# ATxmega256A3B device description
Architecture: AVR8_XMEGA; Family: AVR XMEGA
Registers are 8-bit, access not given, no defined reset value unless marked. A register's access mark holds for its fields unless they carry their own. Offsets are from the block's base; [hi:lo] are bit positions; {n}, {i} and the like mark numbered series; 'fields as' and 'values as' point back to an identical list.

## NVM_FUSES — Fuses
Instances: FUSE 0x00 in fuses
0x00 FUSEBYTE0 reset 0xFF — JTAG User ID
  [7:0] JTAGUSERID
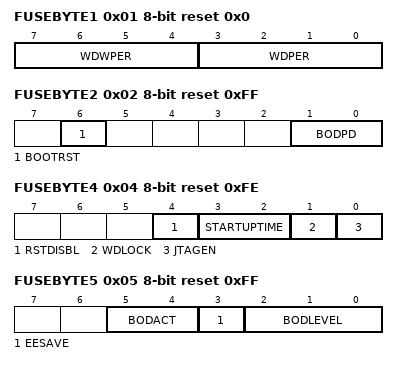
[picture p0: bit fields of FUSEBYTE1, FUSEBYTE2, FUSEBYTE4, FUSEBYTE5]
0x01 FUSEBYTE1 reset 0x0 — Watchdog Configuration
  [7:4] WDWPER — Watchdog Window Timeout Period
    0=8CLK (8 cycles (8ms @ 3.3V)); 1=16CLK (16 cycles (16ms @ 3.3V)); 2=32CLK (32 cycles (32ms @ 3.3V)); 3=64CLK (64 cycles (64ms @ 3.3V)); 4=128CLK (128 cycles (0.125s @ 3.3V)); 5=256CLK (256 cycles (0.25s @ 3.3V)); 6=512CLK (512 cycles (0.5s @ 3.3V)); 7=1KCLK (1K cycles (1s @ 3.3V)); 8=2KCLK (2K cycles (2s @ 3.3V)); 9=4KCLK (4K cycles (4s @ 3.3V)); 10=8KCLK (8K cycles (8s @ 3.3V))
  [3:0] WDPER — Watchdog Timeout Period
    values as WDWPER
0x02 FUSEBYTE2 reset 0xFF — Reset Configuration
  [6] BOOTRST — Boot Loader Section Reset Vector
    0=BOOTLDR (Boot Loader Reset); 1=APPLICATION (Application Reset)
  [1:0] BODPD — BOD Operation in Power-Down Mode
    1=INSAMPLEDMODE (BOD enabled in sampled mode); 2=CONTINOUSLY (BOD enabled continuously); 3=DISABLED (BOD Disabled)
0x04 FUSEBYTE4 reset 0xFE — Start-up Configuration
  [4] RSTDISBL — External Reset Disable
  [3:2] STARTUPTIME
    3=0MS; 1=4MS; 0=64MS
  [1] WDLOCK — Watchdog Timer Lock
  [0] JTAGEN — JTAG Interface Enable
0x05 FUSEBYTE5 reset 0xFF — EESAVE and BOD Level
  [5:4] BODACT — BOD Operation in Active Mode
    values as FUSEBYTE2.BODPD
  [3] EESAVE — Preserve EEPROM Through Chip Erase
  [2:0] BODLEVEL — Brownout Detection Voltage Level
    7=1V6 (1.6 V); 6=1V9 (1.9 V); 5=2V1 (2.1 V); 4=2V4 (2.4 V); 3=2V6 (2.6 V); 2=2V9 (2.9 V); 1=3V2 (3.2 V); 0=3V4 (3.4 V)

## NVM_PROD_SIGNATURES — Production Signatures
Instances: PROD_SIGNATURES 0x00 in prod_signatures
0x00 RCOSC2M — RCOSC 2MHz Calibration Value
0x02 RCOSC32K — RCOSC 32kHz Calibration Value
0x03 RCOSC32M — RCOSC 32MHz Calibration Value
{0x8+i} LOTNUM{i} (i=0..5) — Lot Number Byte {i}, ASCII
0x10 WAFNUM — Wafer Number
0x12 COORDX0 — Wafer Coordinate X Byte 0
0x13 COORDX1 — Wafer Coordinate X Byte 1
0x14 COORDY0 — Wafer Coordinate Y Byte 0
0x15 COORDY1 — Wafer Coordinate Y Byte 1
0x20 ADCACAL0 — ADCA Calibration Byte 0
0x21 ADCACAL1 — ADCA Calibration Byte 1
0x24 ADCBCAL0 — ADCB Calibration Byte 0
0x25 ADCBCAL1 — ADCB Calibration Byte 1
0x2E TEMPSENSE0 — Temperature Sensor Calibration Byte 0
0x2F TEMPSENSE1 — Temperature Sensor Calibration Byte 0
0x30 DACAOFFCAL — DACA Calibration Byte 0
0x31 DACAGAINCAL — DACA Calibration Byte 1
0x32 DACBOFFCAL — DACB Calibration Byte 0
0x33 DACBGAINCAL — DACB Calibration Byte 1

## AC — Analog Comparator
Instances: ACA 0x0380, ACB 0x0390
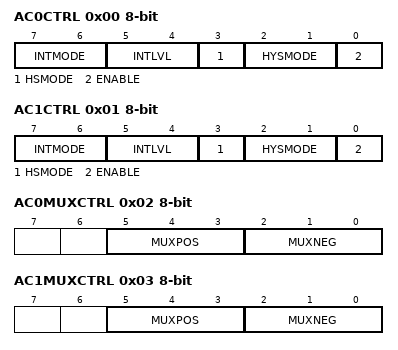
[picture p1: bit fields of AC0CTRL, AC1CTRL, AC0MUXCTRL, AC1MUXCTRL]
0x00 AC0CTRL — Analog Comparator 0 Control
  [7:6] INTMODE — Interrupt Mode
    0=BOTHEDGES (Interrupt on both edges); 2=FALLING (Interrupt on falling edge); 3=RISING (Interrupt on rising edge)
  [5:4] INTLVL — Interrupt Level
    0=OFF (Interrupt disabled); 1=LO (Low level); 2=MED (Medium level); 3=HI (High level)
  [3] HSMODE — High-speed Mode
  [2:1] HYSMODE — Hysteresis Mode
    0=NO (No hysteresis); 1=SMALL (Small hysteresis); 2=LARGE (Large hysteresis)
  [0] ENABLE
0x01 AC1CTRL — Analog Comparator 1 Control
  fields as AC0CTRL
0x02 AC0MUXCTRL — Analog Comparator 0 MUX Control
  [5:3] MUXPOS — MUX Positive Input
    {v}=PIN{v} (v=0..6); 7=DAC (DAC output)
  [2:0] MUXNEG — MUX Negative Input
    0=PIN0; 1=PIN1; 2=PIN3; 3=PIN5; 4=PIN7; 5=DAC (DAC output); 6=BANDGAP (Bandgap Reference); 7=SCALER (Internal voltage scaler)
0x03 AC1MUXCTRL — Analog Comparator 1 MUX Control
  fields as AC0MUXCTRL
0x04 CTRLA — Control Register A
  [0] AC0OUT — Analog Comparator 0 Output Enable
0x05 CTRLB — Control Register B
  [5:0] SCALEFAC — VCC Voltage Scaler Factor
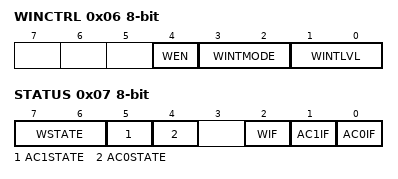
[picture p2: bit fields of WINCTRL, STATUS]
0x06 WINCTRL — Window Mode Control
  [4] WEN — Window Mode Enable
  [3:2] WINTMODE — Window Interrupt Mode
    0=ABOVE (Interrupt on above window); 1=INSIDE (Interrupt on inside window); 2=BELOW (Interrupt on below window); 3=OUTSIDE (Interrupt on outside window)
  [1:0] WINTLVL — Window Interrupt Level
    0=OFF (Interrupt disabled); 1=LO (Low priority); 2=MED (Medium priority); 3=HI (High priority)
0x07 STATUS
  [7:6] WSTATE — Window Mode State
    0=ABOVE (Signal above window); 1=INSIDE (Signal inside window); 2=BELOW (Signal below window)
  [5] AC1STATE — Analog Comparator 1 State
  [4] AC0STATE — Analog Comparator 0 State
  [2] WIF — Window Mode Interrupt Flag
  [1] AC1IF — Analog Comparator 1 Interrupt Flag
  [0] AC0IF — Analog Comparator 0 Interrupt Flag
